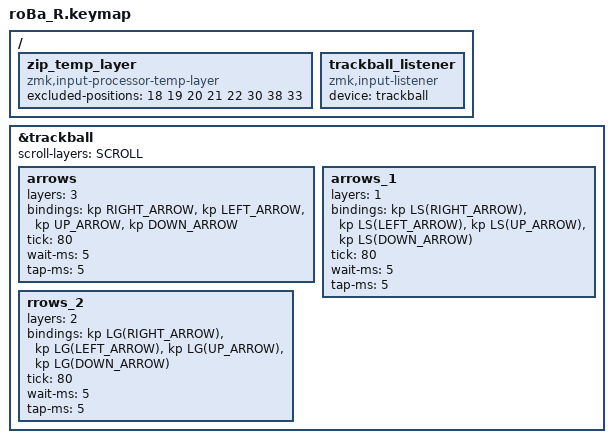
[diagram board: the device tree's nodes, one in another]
#include "roBa_L.keymap"

#include "boards/shields/Test/roBa_R.overlay"

#include <input/processors.dtsi>
/ {
    /omit-if-no-ref/ zip_temp_layer: zip_temp_layer {
        compatible = "zmk,input-processor-temp-layer";
        #input-processor-cells = <2>;
        excluded-positions = <
            18 // J
            19 // K
            20 // L
            21 // ;
            22 // Z
            30 // .
            38 // ,
            33
        >;
    };

    trackball_listener {
        compatible = "zmk,input-listener";
        device = <&trackball>;

        //input-processors = <&zip_temp_layer MOUSE 10000>;
    };
};

&trackball {

    scroll-layers = <SCROLL>;
    // snipe-layers = <3>;

    arrows {
        layers = <3>;
        bindings =
            <&kp RIGHT_ARROW>,
            <&kp LEFT_ARROW>,
            <&kp UP_ARROW>,
            <&kp DOWN_ARROW>;

        tick = <80>;
        wait-ms = <5>;
        tap-ms = <5>;
    };

    arrows_1 {
        layers = <1>;
        bindings =
            <&kp LS(RIGHT_ARROW)>,
            <&kp LS(LEFT_ARROW)>,
            <&kp LS(UP_ARROW)>,
            <&kp LS(DOWN_ARROW)>;

        tick = <80>;
        wait-ms = <5>;
        tap-ms = <5>;
    };

rrows_2 {
        layers = <2>;
        bindings =
            <&kp LG(RIGHT_ARROW)>,
            <&kp LG(LEFT_ARROW)>,
            <&kp LG(UP_ARROW)>,
            <&kp LG(DOWN_ARROW)>;

        tick = <80>;
        wait-ms = <5>;
        tap-ms = <5>;
    };
};
